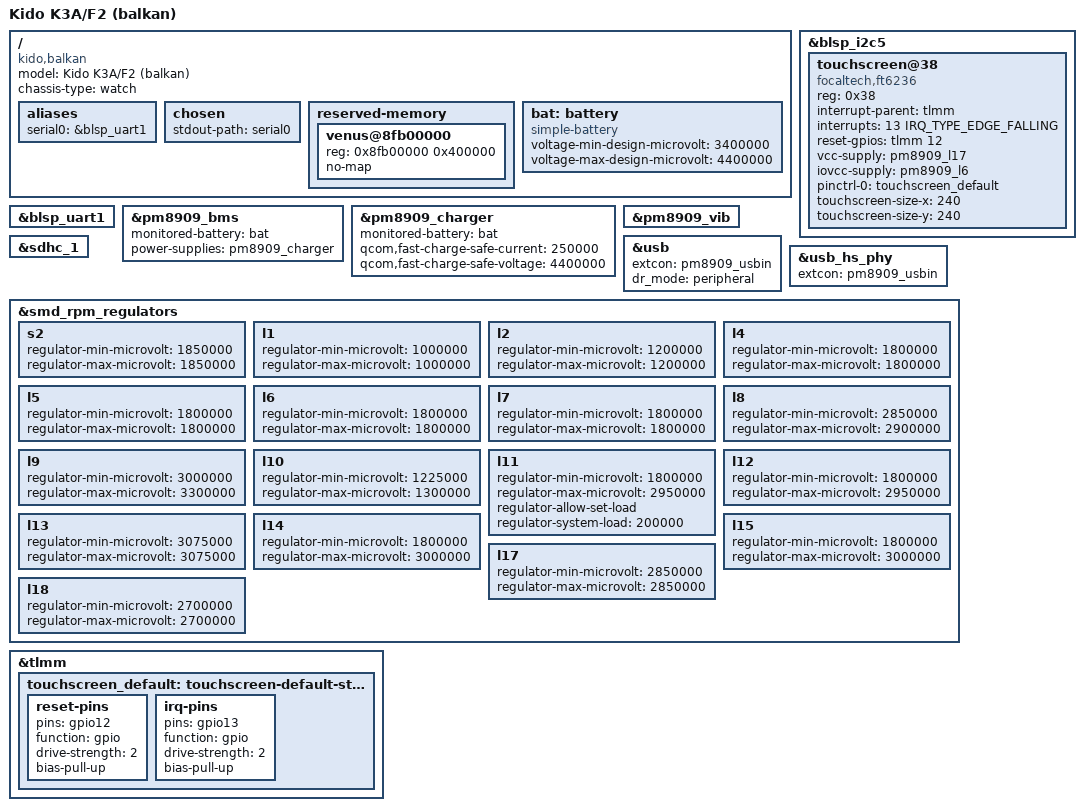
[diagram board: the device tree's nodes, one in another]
// SPDX-License-Identifier: GPL-2.0-only
/*
 * Kido K3A / F2 (balkan) - MSM8909 based child smartwatch
 *
 * The K3A and F2 share one PCB and one device tree. The downstream bootloader
 * carries three DTBs in total (K3A v0, K3A v1, K3A/F2 VN1) and picks one using
 * the "kido,board-id" property: this board reports board-id 0x10.
 *
 * Not enabled:
 *  - Display: the 240x240 ST7796S panel is driven over MIPI DSI in command
 *    mode, but mainline has neither an MDP3 nor a DSI host driver for MSM8909.
 *  - Camera: camss has no MSM8909 support.
 *  - Sensors on blsp_i2c1: declared downstream (mpu6050, apds9900, and one of
 *    mmc3416x/ak8963/qmcX983), but nothing answers on the bus, so their
 *    presence is unconfirmed.
 */

/dts-v1/;

#include "qcom-msm8909-pm8909.dtsi"

#include <dt-bindings/gpio/gpio.h>
#include <dt-bindings/interrupt-controller/irq.h>

/ {
	model = "Kido K3A/F2 (balkan)";
	compatible = "kido,balkan", "qcom,msm8909";
	chassis-type = "watch";

	aliases {
		serial0 = &blsp_uart1;
	};

	chosen {
		stdout-path = "serial0";
	};

	reserved-memory {
		/* Venus firmware, reserved by the downstream bootloader. */
		venus@8fb00000 {
			reg = <0x8fb00000 0x400000>;
			no-map;
		};
	};

	/*
	 * TODO: neither the design capacity nor an OCV/capacity table is known
	 * yet, so capacity reporting will not work until they are added.
	 */
	bat: battery {
		compatible = "simple-battery";
		voltage-min-design-microvolt = <3400000>;
		voltage-max-design-microvolt = <4400000>;
	};
};

&blsp_i2c5 {
	status = "okay";

	touchscreen@38 {
		/*
		 * FocalTech FT3267. It is driven by FocalTech's own downstream
		 * driver but speaks the FT5x06/FT6x06 register protocol. The
		 * compatible below is provisional and has to be confirmed on
		 * hardware.
		 */
		compatible = "focaltech,ft6236";
		reg = <0x38>;

		interrupt-parent = <&tlmm>;
		interrupts = <13 IRQ_TYPE_EDGE_FALLING>;

		reset-gpios = <&tlmm 12 GPIO_ACTIVE_HIGH>;

		vcc-supply = <&pm8909_l17>;
		iovcc-supply = <&pm8909_l6>;

		pinctrl-0 = <&touchscreen_default>;
		pinctrl-names = "default";

		touchscreen-size-x = <240>;
		touchscreen-size-y = <240>;
	};
};

&blsp_uart1 {
	status = "okay";
};

&pm8909_bms {
	monitored-battery = <&bat>;
	power-supplies = <&pm8909_charger>;
	status = "okay";
};

&pm8909_charger {
	monitored-battery = <&bat>;

	/*
	 * The battery is charged to 4.4 V. The current limit is a conservative
	 * value for the small cell used in the watch.
	 */
	qcom,fast-charge-safe-current = <250000>;
	qcom,fast-charge-safe-voltage = <4400000>;
	status = "okay";
};

&pm8909_vib {
	status = "okay";
};

&sdhc_1 {
	status = "okay";
};

&usb {
	extcon = <&pm8909_usbin>;
	dr_mode = "peripheral";
	status = "okay";
};

&usb_hs_phy {
	extcon = <&pm8909_usbin>;
};

/* Voltage limits used by the downstream firmware for this board. */
&smd_rpm_regulators {
	s2 {
		regulator-min-microvolt = <1850000>;
		regulator-max-microvolt = <1850000>;
	};

	l1 {
		regulator-min-microvolt = <1000000>;
		regulator-max-microvolt = <1000000>;
	};

	l2 {
		regulator-min-microvolt = <1200000>;
		regulator-max-microvolt = <1200000>;
	};

	l4 {
		regulator-min-microvolt = <1800000>;
		regulator-max-microvolt = <1800000>;
	};

	l5 {
		regulator-min-microvolt = <1800000>;
		regulator-max-microvolt = <1800000>;
	};

	l6 {
		regulator-min-microvolt = <1800000>;
		regulator-max-microvolt = <1800000>;
	};

	l7 {
		regulator-min-microvolt = <1800000>;
		regulator-max-microvolt = <1800000>;
	};

	l8 {
		regulator-min-microvolt = <2850000>;
		regulator-max-microvolt = <2900000>;
	};

	l9 {
		regulator-min-microvolt = <3000000>;
		regulator-max-microvolt = <3300000>;
	};

	l10 {
		regulator-min-microvolt = <1225000>;
		regulator-max-microvolt = <1300000>;
	};

	l11 {
		regulator-min-microvolt = <1800000>;
		regulator-max-microvolt = <2950000>;
		regulator-allow-set-load;
		regulator-system-load = <200000>;
	};

	l12 {
		regulator-min-microvolt = <1800000>;
		regulator-max-microvolt = <2950000>;
	};

	l13 {
		regulator-min-microvolt = <3075000>;
		regulator-max-microvolt = <3075000>;
	};

	l14 {
		regulator-min-microvolt = <1800000>;
		regulator-max-microvolt = <3000000>;
	};

	l15 {
		regulator-min-microvolt = <1800000>;
		regulator-max-microvolt = <3000000>;
	};

	l17 {
		regulator-min-microvolt = <2850000>;
		regulator-max-microvolt = <2850000>;
	};

	l18 {
		regulator-min-microvolt = <2700000>;
		regulator-max-microvolt = <2700000>;
	};
};

&tlmm {
	touchscreen_default: touchscreen-default-state {
		reset-pins {
			pins = "gpio12";
			function = "gpio";
			drive-strength = <2>;
			bias-pull-up;
		};

		irq-pins {
			pins = "gpio13";
			function = "gpio";
			drive-strength = <2>;
			bias-pull-up;
		};
	};
};
